VERSION ""

NS_ :

BS_:

BO_ 256 PCS_STATE: 7 XXX
 SG_ PCS_ALARM : 1|1@0+ (1,0) [0|1] "" XXX

BU_: XXX
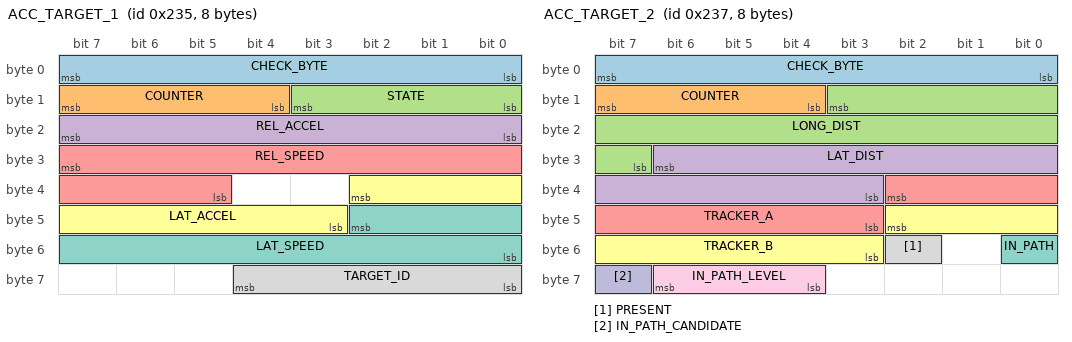
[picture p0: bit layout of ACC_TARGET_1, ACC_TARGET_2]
BO_ 565 ACC_TARGET_1: 8 RADAR
 SG_ CHECK_BYTE : 7|8@0+ (1,0) [0|255] "" RADAR
 SG_ COUNTER : 15|4@0+ (1,0) [0|15] "" RADAR
 SG_ STATE : 11|4@0+ (1,0) [0|15] "" RADAR
 SG_ REL_ACCEL : 23|8@0+ (0.125,-12.5) [-12.5|19.375] "m/s^2" RADAR
 SG_ REL_SPEED : 31|11@0+ (0.125,-128) [-128|127.875] "m/s" RADAR
 SG_ LAT_ACCEL : 34|8@0+ (0.125,-12.5) [-12.5|19.375] "m/s^2" RADAR
 SG_ LAT_SPEED : 42|11@0+ (0.0125,-12.8) [-12.8|12.7875] "m/s" RADAR
 SG_ TARGET_ID : 60|5@0+ (1,0) [0|31] "" RADAR

BO_ 567 ACC_TARGET_2: 8 RADAR
 SG_ CHECK_BYTE : 7|8@0+ (1,0) [0|255] "" RADAR
 SG_ COUNTER : 15|4@0+ (1,0) [0|15] "" RADAR
 SG_ LONG_DIST : 11|13@0+ (0.025,0) [0|204.775] "m" RADAR
 SG_ LAT_DIST : 30|12@0+ (0.01,-20) [-20|20.95] "m" RADAR
 SG_ TRACKER_A : 34|8@0+ (1,0) [0|255] "" RADAR
 SG_ TRACKER_B : 42|8@0+ (1,0) [0|255] "" RADAR
 SG_ IN_PATH : 48|1@0+ (1,0) [0|1] "" RADAR
 SG_ PRESENT : 50|1@0+ (1,0) [0|1] "" RADAR
 SG_ IN_PATH_LEVEL : 62|3@0+ (1,0) [0|7] "" RADAR
 SG_ IN_PATH_CANDIDATE : 63|1@0+ (1,0) [0|1] "" RADAR

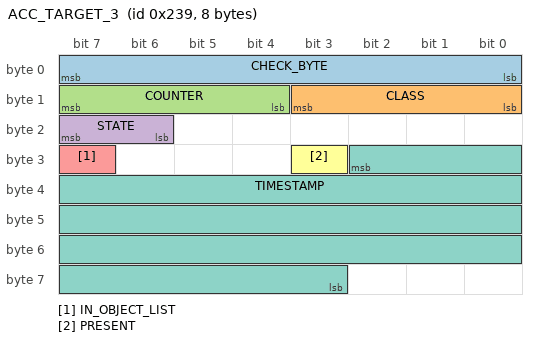
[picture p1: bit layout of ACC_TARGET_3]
BO_ 569 ACC_TARGET_3: 8 RADAR
 SG_ CHECK_BYTE : 7|8@0+ (1,0) [0|255] "" RADAR
 SG_ CLASS : 11|4@0+ (1,0) [0|15] "" RADAR
 SG_ COUNTER : 15|4@0+ (1,0) [0|15] "" RADAR
 SG_ STATE : 23|2@0+ (1,0) [0|3] "" RADAR
 SG_ IN_OBJECT_LIST : 31|1@0+ (1,0) [0|1] "" RADAR
 SG_ PRESENT : 27|1@0+ (1,0) [0|1] "" RADAR
 SG_ TIMESTAMP : 26|32@0+ (1,0) [0|4294967295] "us" RADAR

BO_ 571 ARS510_A23B_COMPANION: 3 RADAR
 SG_ A23B_B0_CHECK_BYTE : 0|8@1+ (1,0) [0|255] "debug" RADAR
 SG_ A23B_STATUS_MUX4 : 8|4@1+ (1,0) [0|15] "state" RADAR
 SG_ A23B_COUNTER4 : 12|4@1+ (1,0) [0|15] "counter" RADAR
 SG_ A23B_B2 : 16|8@1+ (1,0) [0|255] "raw" RADAR
 SG_ A23B_TARGET_WIDTH_CM : 11|12@0+ (1,0) [0|4095] "cm" RADAR

CM_ "Continental ARS510 front radar (Toyota RAV4 2022-25, fwdRadar 8821F0R03100), radar bus: the target the radar's own ACC follows. The 0x80 object list and 0x85 metadata record span many frames and are decoded by ars510-radar (ars510/).";
CM_ BO_ 256 "Radar PCS state, 10 Hz. The first frame after power-up is FF FF (ignore it); zero otherwise, except PCS_ALARM.";
CM_ SG_ 256 PCS_ALARM "Pre-collision alarm: 1 from the same CAN frame as the car-bus PCS alarm (0x283 PCSNOCHG, 0x411 FCW) until it ends; seen in 8 stock alarms on 7 cars, never otherwise.";
CM_ BO_ 565 "ACC target, part 1: 50 Hz, content updated once per 60 ms radar cycle.";
CM_ SG_ 565 STATE "5 = target present, 1 = idle (all other fields zero).";
CM_ SG_ 565 REL_ACCEL "Target acceleration relative to ego.";
CM_ SG_ 565 REL_SPEED "Closing speed relative to ego, negative = closing.";
CM_ SG_ 565 LAT_SPEED "Lateral speed of the ACC target.";
CM_ SG_ 565 LAT_ACCEL "Relative lateral acceleration of the ACC target.";
CM_ SG_ 565 TARGET_ID "Changes when the radar switches to a different target.";
CM_ BO_ 567 "ACC target, part 2: 50 Hz.";
CM_ SG_ 567 LONG_DIST "Distance from the radar.";
CM_ SG_ 567 LAT_DIST "Lateral position, left positive.";
CM_ SG_ 567 PRESENT "1 = target present.";
CM_ SG_ 567 IN_PATH "1 while the target is confirmed in the path (level 5).";
CM_ SG_ 567 IN_PATH_CANDIDATE "1 while the target is a candidate (levels 4-2).";
CM_ SG_ 567 IN_PATH_LEVEL "In-path level 5, 4, 3, 2; steps to the neighbouring level only; lower levels sit farther from the path.";
CM_ SG_ 567 LONG_DIST "Distance of the ACC target.";
CM_ BO_ 569 "ACC target, part 3: 50 Hz.";
CM_ SG_ 569 STATE "1 with an ACC target, 2 idle.";
CM_ SG_ 569 TIMESTAMP "Radar cycle clock: changes once per 60 ms radar cycle, when the ACC target is recomputed.";
CM_ BO_ 571 "50 Hz companion of the ACC target (3 bytes): CRC-8, counter and the target width in cm.";
